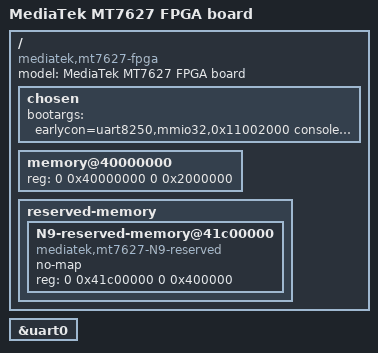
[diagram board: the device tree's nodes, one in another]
/*
 * Copyright (c) 2017 MediaTek Inc.
 * Author: Dehui.Sun <dehui.sun@mediatek.com>
 *
 * This program is free software; you can redistribute it and/or modify
 * it under the terms of the GNU General Public License version 2 as
 * published by the Free Software Foundation.
 *
 * This program is distributed in the hope that it will be useful,
 * but WITHOUT ANY WARRANTY; without even the implied warranty of
 * MERCHANTABILITY or FITNESS FOR A PARTICULAR PURPOSE.  See the
 * GNU General Public License for more details.
 */

/dts-v1/;
#include "mt7627-fpga.dtsi"

/ {
	model = "MediaTek MT7627 FPGA board";
	compatible = "mediatek,mt7627-fpga", "mediatek,mt7627";

	chosen {
		bootargs = "earlycon=uart8250,mmio32,0x11002000 console=ttyS0,921600n1 \
root=/dev/ram loglevel=8";
	};

	memory@40000000 {
		device_type = "memory";
		reg = <0 0x40000000 0 0x2000000>;
	};

	reserved-memory {
		#address-cells = <2>;
		#size-cells = <2>;
		ranges;

		N9-reserved-memory@41c00000 {
			compatible = "mediatek,mt7627-N9-reserved";
			no-map;
			reg = <0 0x41c00000 0 0x400000>;
		};
	};
};

&uart0 {
	status = "okay";
};

